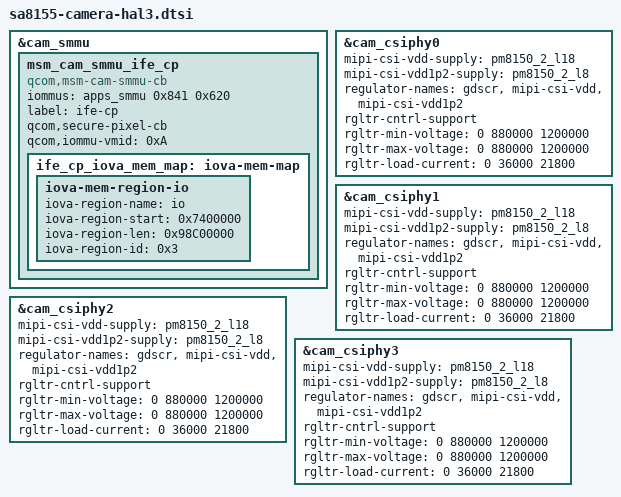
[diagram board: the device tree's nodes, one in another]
#include "sm8150-camera.dtsi"
#include "sa8155-camera-sensor.dtsi"

&cam_smmu {
	msm_cam_smmu_ife_cp {
		compatible = "qcom,msm-cam-smmu-cb";
		iommus = <&apps_smmu 0x841 0x620>;
		label = "ife-cp";
		qcom,secure-pixel-cb;
		qcom,iommu-vmid = <0xA>; /* VMID_CP_PIXEL */
		ife_cp_iova_mem_map: iova-mem-map {
			/* IO region is approximately 2.5 GB */
			iova-mem-region-io {
				iova-region-name = "io";
				iova-region-start = <0x7400000>;
				iova-region-len = <0x98C00000>;
				iova-region-id = <0x3>;
				status = "ok";
			};
		};
	};
};

&cam_csiphy0 {
	mipi-csi-vdd-supply = <&pm8150_2_l18>;
	mipi-csi-vdd1p2-supply = <&pm8150_2_l8>;
	regulator-names = "gdscr", "mipi-csi-vdd", "mipi-csi-vdd1p2";
	rgltr-cntrl-support;
	rgltr-min-voltage = <0 880000 1200000>;
	rgltr-max-voltage = <0 880000 1200000>;
	rgltr-load-current = <0 36000 21800>;
};

&cam_csiphy1 {
	mipi-csi-vdd-supply = <&pm8150_2_l18>;
	mipi-csi-vdd1p2-supply = <&pm8150_2_l8>;
	regulator-names = "gdscr", "mipi-csi-vdd", "mipi-csi-vdd1p2";
	rgltr-cntrl-support;
	rgltr-min-voltage = <0 880000 1200000>;
	rgltr-max-voltage = <0 880000 1200000>;
	rgltr-load-current = <0 36000 21800>;
};

&cam_csiphy2 {
	mipi-csi-vdd-supply = <&pm8150_2_l18>;
	mipi-csi-vdd1p2-supply = <&pm8150_2_l8>;
	regulator-names = "gdscr", "mipi-csi-vdd", "mipi-csi-vdd1p2";
	rgltr-cntrl-support;
	rgltr-min-voltage = <0 880000 1200000>;
	rgltr-max-voltage = <0 880000 1200000>;
	rgltr-load-current = <0 36000 21800>;
};

&cam_csiphy3 {
	mipi-csi-vdd-supply = <&pm8150_2_l18>;
	mipi-csi-vdd1p2-supply = <&pm8150_2_l8>;
	regulator-names = "gdscr", "mipi-csi-vdd", "mipi-csi-vdd1p2";
	rgltr-cntrl-support;
	rgltr-min-voltage = <0 880000 1200000>;
	rgltr-max-voltage = <0 880000 1200000>;
	rgltr-load-current = <0 36000 21800>;
};
